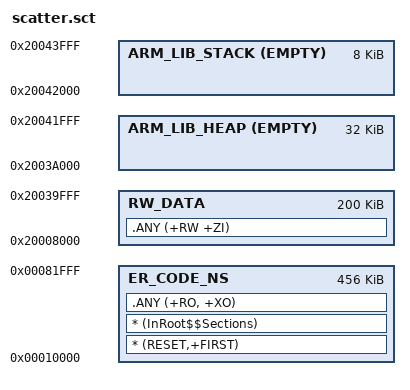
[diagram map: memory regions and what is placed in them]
LR_CODE_NS 0x10000 0x72000 {
  ER_CODE_NS 0x10000 0x72000 {
  	* (RESET,+FIRST)
    * (InRoot$$Sections)
    .ANY (+RO, +XO)
  }
  RW_DATA 0x20008000 0x32000 {
    .ANY (+RW +ZI)
  }
  ARM_LIB_HEAP 0x2003A000 EMPTY 0x8000 {
  }
  ARM_LIB_STACK 0x20042000 EMPTY 0x2000 {
  }
}
